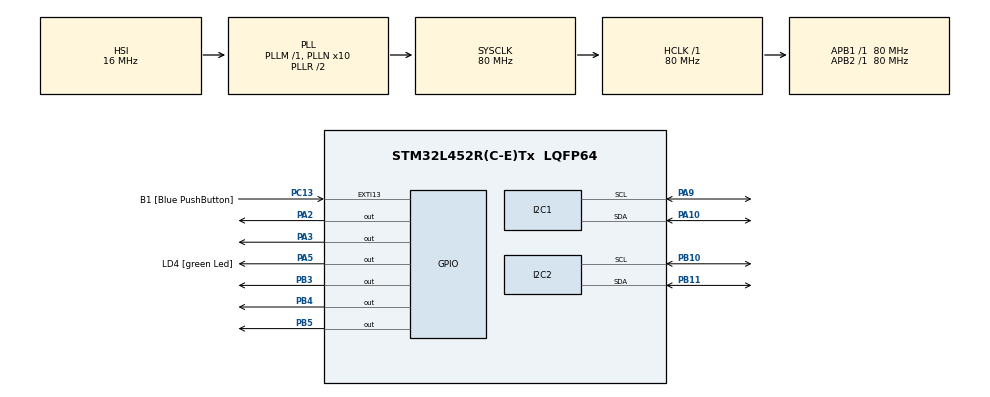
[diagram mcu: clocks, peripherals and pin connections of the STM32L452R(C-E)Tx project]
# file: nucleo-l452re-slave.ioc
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FREERTOS.Tasks01=ControllerTask,24,1024,StartControllerTask,Default,NULL,Dynamic,NULL,NULL;Motor1Task,8,256,StartMotor1Task,Default,NULL,Dynamic,NULL,NULL;Motor2Task,8,256,StartMotor2Task,Default,NULL,Dynamic,NULL,NULL
FREERTOS.configCHECK_FOR_STACK_OVERFLOW=0
FREERTOS.configTOTAL_HEAP_SIZE=10000
FREERTOS.configUSE_MALLOC_FAILED_HOOK=0
I2C1.OwnAddress=0x18
I2C1.Timing=0x10909CEC
I2C2.OwnAddress=0x19
I2C2.Timing=0x10909CEC
Mcu.Family=STM32L4
Mcu.Name=STM32L452R(C-E)Tx
Mcu.Package=LQFP64
NVIC.I2C1_ER_IRQn=true\:5\:0\:false\:false\:true\:true\:true\:true
NVIC.I2C1_EV_IRQn=true\:5\:0\:false\:false\:true\:true\:true\:true
NVIC.I2C2_ER_IRQn=true\:5\:0\:false\:false\:true\:true\:true\:true
NVIC.I2C2_EV_IRQn=true\:5\:0\:false\:false\:true\:true\:true\:true
NVIC.PriorityGroup=NVIC_PRIORITYGROUP_4
NVIC.TIM1_UP_TIM16_IRQn=true\:0\:0\:false\:false\:true\:false\:false\:true
NVIC.TimeBase=TIM1_UP_TIM16_IRQn
NVIC.TimeBaseIP=TIM1
PA10.Mode=I2C
PA10.Signal=I2C1_SDA
PA13\ (JTMS/SWDIO).GPIO_Label=TMS
PA13\ (JTMS/SWDIO).Mode=Serial_Wire
PA13\ (JTMS/SWDIO).Signal=SYS_JTMS-SWDIO
PA14\ (JTCK/SWCLK).GPIO_Label=TCK
PA14\ (JTCK/SWCLK).Mode=Serial_Wire
PA14\ (JTCK/SWCLK).Signal=SYS_JTCK-SWCLK
PA2.Signal=GPIO_Output
PA3.Signal=GPIO_Output
PA5.GPIO_Label=LD4 [green Led]
PA5.GPIO_ModeDefaultOutputPP=GPIO_MODE_OUTPUT_PP
PA5.GPIO_PuPd=GPIO_NOPULL
PA5.GPIO_Speed=GPIO_SPEED_FREQ_LOW
PA5.Signal=GPIO_Output
PA9.Mode=I2C
PA9.Signal=I2C1_SCL
PB10.Mode=I2C
PB10.Signal=I2C2_SCL
PB11.Mode=I2C
PB11.Signal=I2C2_SDA
PB3\ (JTDO/TRACESWO).Signal=GPIO_Output
PB4\ (NJTRST).Signal=GPIO_Output
PB5.Signal=GPIO_Output
PC13.GPIO_Label=B1 [Blue PushButton]
PC13.GPIO_ModeDefaultEXTI=GPIO_MODE_IT_FALLING
PC13.GPIO_PuPd=GPIO_NOPULL
PC13.Signal=GPXTI13
PC14-OSC32_IN\ (PC14).Mode=LSE-External-Oscillator
PC14-OSC32_IN\ (PC14).Signal=RCC_OSC32_IN
PC15-OSC32_OUT\ (PC15).Mode=LSE-External-Oscillator
PC15-OSC32_OUT\ (PC15).Signal=RCC_OSC32_OUT
PH0-OSC_IN\ (PH0).Signal=RCC_OSC_IN
PH1-OSC_OUT\ (PH1).Signal=RCC_OSC_OUT
ProjectManager.HeapSize=0x200
ProjectManager.StackSize=0x400
ProjectManager.TargetToolchain=Makefile
RCC.ADCFreq_Value=64000000
RCC.AHBFreq_Value=80000000
RCC.APB1Freq_Value=80000000
RCC.APB1TimFreq_Value=80000000
RCC.APB2Freq_Value=80000000
RCC.APB2TimFreq_Value=80000000
RCC.CortexFreq_Value=80000000
RCC.HCLKFreq_Value=80000000
RCC.HSE_VALUE=8000000
RCC.HSI48_VALUE=48000000
RCC.HSI_VALUE=16000000
RCC.MSI_VALUE=4000000
RCC.PLLN=10
RCC.PLLSourceVirtual=RCC_PLLSOURCE_HSI
RCC.PREFETCH_ENABLE=1
RCC.SYSCLKFreq_VALUE=80000000
RCC.SYSCLKSource=RCC_SYSCLKSOURCE_PLLCLK
RCC.USBFreq_Value=64000000
RCC.VCOOutputFreq_Value=160000000
VP_FREERTOS_VS_CMSIS_V2.Mode=CMSIS_V2
VP_SYS_VS_tim1.Mode=TIM1
board=NUCLEO-L452RE

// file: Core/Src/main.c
/* USER CODE BEGIN Header */
/**
  ******************************************************************************
  * @file           : main.c
  * @brief          : Main program body
  ******************************************************************************
  * @attention
  *
  * <h2><center>&copy; Copyright (c) 2021 STMicroelectronics.
  * All rights reserved.</center></h2>
  *
  * This software component is licensed by ST under BSD 3-Clause license,
  * the "License"; You may not use this file except in compliance with the
  * License. You may obtain a copy of the License at:
  *                        opensource.org/licenses/BSD-3-Clause
  *
  ******************************************************************************
  */
/* USER CODE END Header */
#include "main.h"
#include "cmsis_os.h"

/* USER CODE BEGIN Includes */
#include "controller.h"
/* USER CODE END Includes */

I2C_HandleTypeDef hi2c1;
I2C_HandleTypeDef hi2c2;

/* Definitions for ControllerTask */
osThreadId_t ControllerTaskHandle;
const osThreadAttr_t ControllerTask_attributes = {
  .name = "ControllerTask",
  .stack_size = 1024 * 4,
  .priority = (osPriority_t) osPriorityNormal,
};
/* Definitions for Motor1Task */
osThreadId_t Motor1TaskHandle;
const osThreadAttr_t Motor1Task_attributes = {
  .name = "Motor1Task",
  .stack_size = 256 * 4,
  .priority = (osPriority_t) osPriorityLow,
};
/* Definitions for Motor2Task */
osThreadId_t Motor2TaskHandle;
const osThreadAttr_t Motor2Task_attributes = {
  .name = "Motor2Task",
  .stack_size = 256 * 4,
  .priority = (osPriority_t) osPriorityLow,
};

void SystemClock_Config(void);
static void MX_GPIO_Init(void);
static void MX_I2C1_Init(void);
static void MX_I2C2_Init(void);
void StartControllerTask(void *argument);
void StartMotor1Task(void *argument);
void StartMotor2Task(void *argument);

int main(void)
{

  /* MCU Configuration--------------------------------------------------------*/

  /* Reset of all peripherals, Initializes the Flash interface and the Systick. */
  HAL_Init();

  /* Configure the system clock */
  SystemClock_Config();

  /* Initialize all configured peripherals */
  MX_GPIO_Init();
  MX_I2C1_Init();
  MX_I2C2_Init();

  /* Init scheduler */
  osKernelInitialize();

  /* Create the thread(s) */
  /* creation of ControllerTask */
  ControllerTaskHandle = osThreadNew(StartControllerTask, NULL, &ControllerTask_attributes);

  /* creation of Motor1Task */
  Motor1TaskHandle = osThreadNew(StartMotor1Task, NULL, &Motor1Task_attributes);

  /* creation of Motor2Task */
  Motor2TaskHandle = osThreadNew(StartMotor2Task, NULL, &Motor2Task_attributes);

  /* Start scheduler */
  osKernelStart();

  /* We should never get here as control is now taken by the scheduler */
  /* Infinite loop */
  while (1) {

  }
}

void SystemClock_Config(void)
{
  RCC_OscInitTypeDef RCC_OscInitStruct = {0};
  RCC_ClkInitTypeDef RCC_ClkInitStruct = {0};
  RCC_PeriphCLKInitTypeDef PeriphClkInit = {0};

  /** Initializes the RCC Oscillators according to the specified parameters
  * in the RCC_OscInitTypeDef structure.
  */
  RCC_OscInitStruct.OscillatorType = RCC_OSCILLATORTYPE_HSI;
  RCC_OscInitStruct.HSIState = RCC_HSI_ON;
  RCC_OscInitStruct.HSICalibrationValue = RCC_HSICALIBRATION_DEFAULT;
  RCC_OscInitStruct.PLL.PLLState = RCC_PLL_ON;
  RCC_OscInitStruct.PLL.PLLSource = RCC_PLLSOURCE_HSI;
  RCC_OscInitStruct.PLL.PLLM = 1;
  RCC_OscInitStruct.PLL.PLLN = 10;
  RCC_OscInitStruct.PLL.PLLP = RCC_PLLP_DIV7;
  RCC_OscInitStruct.PLL.PLLQ = RCC_PLLQ_DIV2;
  RCC_OscInitStruct.PLL.PLLR = RCC_PLLR_DIV2;
  if (HAL_RCC_OscConfig(&RCC_OscInitStruct) != HAL_OK)
  {
    Error_Handler();
  }
  /** Initializes the CPU, AHB and APB buses clocks
  */
  RCC_ClkInitStruct.ClockType = RCC_CLOCKTYPE_HCLK|RCC_CLOCKTYPE_SYSCLK
                              |RCC_CLOCKTYPE_PCLK1|RCC_CLOCKTYPE_PCLK2;
  RCC_ClkInitStruct.SYSCLKSource = RCC_SYSCLKSOURCE_PLLCLK;
  RCC_ClkInitStruct.AHBCLKDivider = RCC_SYSCLK_DIV1;
  RCC_ClkInitStruct.APB1CLKDivider = RCC_HCLK_DIV1;
  RCC_ClkInitStruct.APB2CLKDivider = RCC_HCLK_DIV1;

  if (HAL_RCC_ClockConfig(&RCC_ClkInitStruct, FLASH_LATENCY_4) != HAL_OK)
  {
    Error_Handler();
  }
  PeriphClkInit.PeriphClockSelection = RCC_PERIPHCLK_I2C1|RCC_PERIPHCLK_I2C2;
  PeriphClkInit.I2c1ClockSelection = RCC_I2C1CLKSOURCE_PCLK1;
  PeriphClkInit.I2c2ClockSelection = RCC_I2C2CLKSOURCE_PCLK1;
  if (HAL_RCCEx_PeriphCLKConfig(&PeriphClkInit) != HAL_OK)
  {
    Error_Handler();
  }
  /** Configure the main internal regulator output voltage
  */
  if (HAL_PWREx_ControlVoltageScaling(PWR_REGULATOR_VOLTAGE_SCALE1) != HAL_OK)
  {
    Error_Handler();
  }
}

static void MX_I2C1_Init(void)
{

  hi2c1.Instance = I2C1;
  hi2c1.Init.Timing = 0x10909CEC;
  hi2c1.Init.OwnAddress1 = 48;
  hi2c1.Init.AddressingMode = I2C_ADDRESSINGMODE_7BIT;
  hi2c1.Init.DualAddressMode = I2C_DUALADDRESS_DISABLE;
  hi2c1.Init.OwnAddress2 = 0;
  hi2c1.Init.OwnAddress2Masks = I2C_OA2_NOMASK;
  hi2c1.Init.GeneralCallMode = I2C_GENERALCALL_DISABLE;
  hi2c1.Init.NoStretchMode = I2C_NOSTRETCH_DISABLE;
  if (HAL_I2C_Init(&hi2c1) != HAL_OK)
  {
    Error_Handler();
  }
  /** Configure Analogue filter
  */
  if (HAL_I2CEx_ConfigAnalogFilter(&hi2c1, I2C_ANALOGFILTER_ENABLE) != HAL_OK)
  {
    Error_Handler();
  }
  /** Configure Digital filter
  */
  if (HAL_I2CEx_ConfigDigitalFilter(&hi2c1, 0) != HAL_OK)
  {
    Error_Handler();
  }

}

static void MX_I2C2_Init(void)
{

  hi2c2.Instance = I2C2;
  hi2c2.Init.Timing = 0x10909CEC;
  hi2c2.Init.OwnAddress1 = 50;
  hi2c2.Init.AddressingMode = I2C_ADDRESSINGMODE_7BIT;
  hi2c2.Init.DualAddressMode = I2C_DUALADDRESS_DISABLE;
  hi2c2.Init.OwnAddress2 = 0;
  hi2c2.Init.OwnAddress2Masks = I2C_OA2_NOMASK;
  hi2c2.Init.GeneralCallMode = I2C_GENERALCALL_DISABLE;
  hi2c2.Init.NoStretchMode = I2C_NOSTRETCH_DISABLE;
  if (HAL_I2C_Init(&hi2c2) != HAL_OK)
  {
    Error_Handler();
  }
  /** Configure Analogue filter
  */
  if (HAL_I2CEx_ConfigAnalogFilter(&hi2c2, I2C_ANALOGFILTER_ENABLE) != HAL_OK)
  {
    Error_Handler();
  }
  /** Configure Digital filter
  */
  if (HAL_I2CEx_ConfigDigitalFilter(&hi2c2, 0) != HAL_OK)
  {
    Error_Handler();
  }

}

static void MX_GPIO_Init(void)
{
  GPIO_InitTypeDef GPIO_InitStruct = {0};

  /* GPIO Ports Clock Enable */
  __HAL_RCC_GPIOC_CLK_ENABLE();
  __HAL_RCC_GPIOH_CLK_ENABLE();
  __HAL_RCC_GPIOA_CLK_ENABLE();
  __HAL_RCC_GPIOB_CLK_ENABLE();

  /*Configure GPIO pin Output Level */
  HAL_GPIO_WritePin(GPIOA, GPIO_PIN_2|GPIO_PIN_3|LD4_Pin, GPIO_PIN_RESET);

  /*Configure GPIO pin Output Level */
  HAL_GPIO_WritePin(GPIOB, GPIO_PIN_3|GPIO_PIN_4|GPIO_PIN_5, GPIO_PIN_RESET);

  /*Configure GPIO pin : B1_Pin */
  GPIO_InitStruct.Pin = B1_Pin;
  GPIO_InitStruct.Mode = GPIO_MODE_IT_FALLING;
  GPIO_InitStruct.Pull = GPIO_NOPULL;
  HAL_GPIO_Init(B1_GPIO_Port, &GPIO_InitStruct);

  /*Configure GPIO pins : PA2 PA3 LD4_Pin */
  GPIO_InitStruct.Pin = GPIO_PIN_2|GPIO_PIN_3|LD4_Pin;
  GPIO_InitStruct.Mode = GPIO_MODE_OUTPUT_PP;
  GPIO_InitStruct.Pull = GPIO_NOPULL;
  GPIO_InitStruct.Speed = GPIO_SPEED_FREQ_LOW;
  HAL_GPIO_Init(GPIOA, &GPIO_InitStruct);

  /*Configure GPIO pins : PB3 PB4 PB5 */
  GPIO_InitStruct.Pin = GPIO_PIN_3|GPIO_PIN_4|GPIO_PIN_5;
  GPIO_InitStruct.Mode = GPIO_MODE_OUTPUT_PP;
  GPIO_InitStruct.Pull = GPIO_NOPULL;
  GPIO_InitStruct.Speed = GPIO_SPEED_FREQ_LOW;
  HAL_GPIO_Init(GPIOB, &GPIO_InitStruct);

}

void StartControllerTask(void *argument)
{
  /* USER CODE BEGIN 5 */
  ControllerTaskInit();
  /* Infinite loop */
  for(;;) {
    ControllerTaskLoop();
    osDelay(1);
  }
  /* USER CODE END 5 */
}

void StartMotor1Task(void *argument)
{
  /* USER CODE BEGIN StartMotor1Task */
  /* Infinite loop */
  for(;;) {
    Motor1TaskLoop();
    osDelay(1);
  }
  /* USER CODE END StartMotor1Task */
}

void StartMotor2Task(void *argument)
{
  /* USER CODE BEGIN StartMotor2Task */
  /* Infinite loop */
  for(;;) {
    Motor2TaskLoop();
    osDelay(1);
  }
  /* USER CODE END StartMotor2Task */
}

 /**
  * @brief  Period elapsed callback in non blocking mode
  * @note   This function is called  when TIM1 interrupt took place, inside
  * HAL_TIM_IRQHandler(). It makes a direct call to HAL_IncTick() to increment
  * a global variable "uwTick" used as application time base.
  * @param  htim : TIM handle
  * @retval None
  */
void HAL_TIM_PeriodElapsedCallback(TIM_HandleTypeDef *htim)
{
  if (htim->Instance == TIM1) {
    HAL_IncTick();
  }
}

void Error_Handler(void)
{
  __disable_irq();
  while (1)
  {
  }
}

/************************ (C) COPYRIGHT STMicroelectronics *****END OF FILE****/
